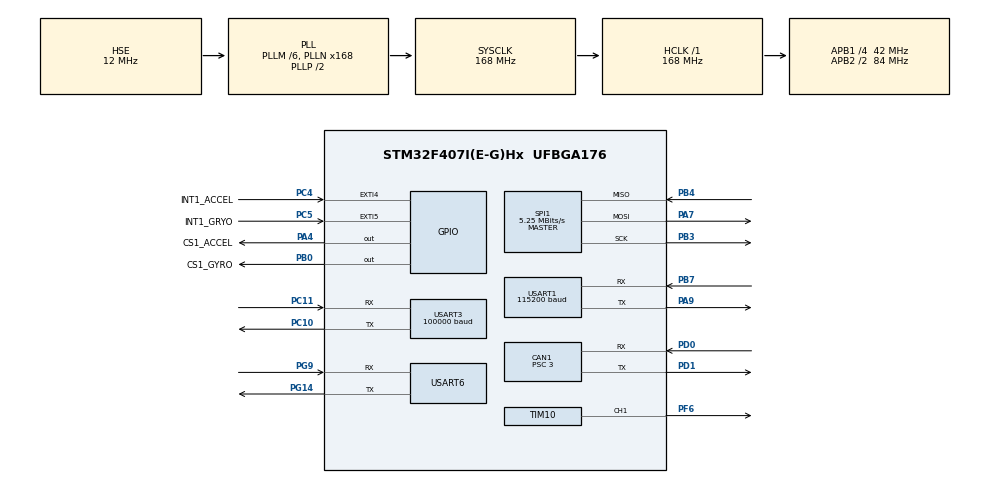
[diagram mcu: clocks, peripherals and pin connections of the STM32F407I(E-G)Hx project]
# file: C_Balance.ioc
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CAN1.ABOM=ENABLE
CAN1.AWUM=ENABLE
CAN1.BS1=CAN_BS1_9TQ
CAN1.BS2=CAN_BS2_4TQ
CAN1.CalculateBaudRate=1000000
CAN1.CalculateTimeBit=1000
CAN1.CalculateTimeQuantum=71.42857142857143
CAN1.Prescaler=3
CAN1.TXFP=ENABLE
Dma.Request0=SPI1_RX
Dma.Request1=SPI1_TX
Dma.Request2=USART3_RX
Dma.Request3=USART1_RX
Dma.Request4=USART1_TX
Dma.SPI1_RX.0.Direction=DMA_PERIPH_TO_MEMORY
Dma.SPI1_RX.0.FIFOMode=DMA_FIFOMODE_DISABLE
Dma.SPI1_RX.0.Instance=DMA2_Stream0
Dma.SPI1_RX.0.MemDataAlignment=DMA_MDATAALIGN_BYTE
Dma.SPI1_RX.0.MemInc=DMA_MINC_ENABLE
Dma.SPI1_RX.0.Mode=DMA_NORMAL
Dma.SPI1_RX.0.PeriphDataAlignment=DMA_PDATAALIGN_BYTE
Dma.SPI1_RX.0.PeriphInc=DMA_PINC_DISABLE
Dma.SPI1_RX.0.Priority=DMA_PRIORITY_VERY_HIGH
Dma.SPI1_TX.1.Direction=DMA_MEMORY_TO_PERIPH
Dma.SPI1_TX.1.FIFOMode=DMA_FIFOMODE_DISABLE
Dma.SPI1_TX.1.Instance=DMA2_Stream3
Dma.SPI1_TX.1.MemDataAlignment=DMA_MDATAALIGN_BYTE
Dma.SPI1_TX.1.MemInc=DMA_MINC_ENABLE
Dma.SPI1_TX.1.Mode=DMA_NORMAL
Dma.SPI1_TX.1.PeriphDataAlignment=DMA_PDATAALIGN_BYTE
Dma.SPI1_TX.1.PeriphInc=DMA_PINC_DISABLE
Dma.SPI1_TX.1.Priority=DMA_PRIORITY_HIGH
Dma.USART1_RX.3.Direction=DMA_PERIPH_TO_MEMORY
Dma.USART1_RX.3.FIFOMode=DMA_FIFOMODE_DISABLE
Dma.USART1_RX.3.Instance=DMA2_Stream2
Dma.USART1_RX.3.MemDataAlignment=DMA_MDATAALIGN_BYTE
Dma.USART1_RX.3.MemInc=DMA_MINC_ENABLE
Dma.USART1_RX.3.Mode=DMA_CIRCULAR
Dma.USART1_RX.3.PeriphDataAlignment=DMA_PDATAALIGN_BYTE
Dma.USART1_RX.3.PeriphInc=DMA_PINC_DISABLE
Dma.USART1_RX.3.Priority=DMA_PRIORITY_LOW
Dma.USART1_TX.4.Direction=DMA_MEMORY_TO_PERIPH
Dma.USART1_TX.4.FIFOMode=DMA_FIFOMODE_DISABLE
Dma.USART1_TX.4.Instance=DMA2_Stream7
Dma.USART1_TX.4.MemDataAlignment=DMA_MDATAALIGN_BYTE
Dma.USART1_TX.4.MemInc=DMA_MINC_ENABLE
Dma.USART1_TX.4.Mode=DMA_NORMAL
Dma.USART1_TX.4.PeriphDataAlignment=DMA_PDATAALIGN_BYTE
Dma.USART1_TX.4.PeriphInc=DMA_PINC_DISABLE
Dma.USART1_TX.4.Priority=DMA_PRIORITY_LOW
Dma.USART3_RX.2.Direction=DMA_PERIPH_TO_MEMORY
Dma.USART3_RX.2.FIFOMode=DMA_FIFOMODE_DISABLE
Dma.USART3_RX.2.Instance=DMA1_Stream1
Dma.USART3_RX.2.MemDataAlignment=DMA_MDATAALIGN_BYTE
Dma.USART3_RX.2.MemInc=DMA_MINC_ENABLE
Dma.USART3_RX.2.Mode=DMA_CIRCULAR
Dma.USART3_RX.2.PeriphDataAlignment=DMA_PDATAALIGN_BYTE
Dma.USART3_RX.2.PeriphInc=DMA_PINC_DISABLE
Dma.USART3_RX.2.Priority=DMA_PRIORITY_HIGH
FREERTOS.Tasks01=defaultTask,0,128,StartDefaultTask,Default,NULL,Dynamic,NULL,NULL;Priority_H1,2,1024,Task_H1,As weak,NULL,Dynamic,NULL,NULL;Priority_H2,2,1024,Task_H2,As weak,NULL,Dynamic,NULL,NULL;Priority_M,1,1024,Task_M,As weak,NULL,Dynamic,NULL,NULL
Mcu.Family=STM32F4
Mcu.Name=STM32F407I(E-G)Hx
Mcu.Package=UFBGA176
NVIC.CAN1_RX0_IRQn=true\:5\:0\:false\:false\:true\:true\:true\:true\:true
NVIC.DMA1_Stream1_IRQn=true\:5\:0\:false\:false\:true\:true\:false\:true\:true
NVIC.DMA2_Stream0_IRQn=true\:5\:0\:false\:false\:true\:true\:false\:true\:true
NVIC.DMA2_Stream2_IRQn=true\:5\:0\:false\:false\:true\:true\:false\:true\:true
NVIC.DMA2_Stream3_IRQn=true\:5\:0\:false\:false\:true\:true\:false\:true\:true
NVIC.DMA2_Stream7_IRQn=true\:5\:0\:false\:false\:true\:true\:false\:true\:true
NVIC.EXTI4_IRQn=true\:5\:0\:false\:false\:true\:true\:true\:true\:true
NVIC.EXTI9_5_IRQn=true\:5\:0\:false\:false\:true\:true\:true\:true\:true
NVIC.PriorityGroup=NVIC_PRIORITYGROUP_4
NVIC.TIM2_IRQn=true\:15\:0\:false\:false\:true\:false\:false\:true\:true
NVIC.TimeBase=TIM2_IRQn
NVIC.TimeBaseIP=TIM2
NVIC.USART1_IRQn=true\:5\:0\:false\:false\:true\:true\:true\:true\:true
NVIC.USART3_IRQn=true\:5\:0\:false\:false\:true\:true\:true\:true\:true
PA13.Mode=Serial_Wire
PA13.Signal=SYS_JTMS-SWDIO
PA14.Mode=Serial_Wire
PA14.Signal=SYS_JTCK-SWCLK
PA4.GPIO_Label=CS1_ACCEL
PA4.GPIO_PuPd=GPIO_PULLUP
PA4.GPIO_Speed=GPIO_SPEED_FREQ_HIGH
PA4.PinState=GPIO_PIN_SET
PA4.Signal=GPIO_Output
PA7.GPIO_PuPd=GPIO_PULLUP
PA7.Mode=Full_Duplex_Master
PA7.Signal=SPI1_MOSI
PA9.Mode=Asynchronous
PA9.Signal=USART1_TX
PB0.GPIO_Label=CS1_GYRO
PB0.GPIO_PuPd=GPIO_PULLUP
PB0.GPIO_Speed=GPIO_SPEED_FREQ_HIGH
PB0.PinState=GPIO_PIN_SET
PB0.Signal=GPIO_Output
PB3.GPIO_PuPd=GPIO_PULLUP
PB3.Mode=Full_Duplex_Master
PB3.Signal=SPI1_SCK
PB4.GPIO_PuPd=GPIO_PULLUP
PB4.Mode=Full_Duplex_Master
PB4.Signal=SPI1_MISO
PB7.Mode=Asynchronous
PB7.Signal=USART1_RX
PC10.Mode=Asynchronous
PC10.Signal=USART3_TX
PC11.Mode=Asynchronous
PC11.Signal=USART3_RX
PC4.GPIO_Label=INT1_ACCEL
PC4.GPIO_ModeDefaultEXTI=GPIO_MODE_IT_FALLING
PC4.GPIO_PuPd=GPIO_PULLUP
PC4.Signal=GPXTI4
PC5.GPIO_Label=INT1_GRYO
PC5.GPIO_ModeDefaultEXTI=GPIO_MODE_IT_FALLING
PC5.GPIO_PuPd=GPIO_PULLUP
PC5.Signal=GPXTI5
PD0.Mode=CAN_Activate
PD0.Signal=CAN1_RX
PD1.Mode=CAN_Activate
PD1.Signal=CAN1_TX
PF6.GPIO_PuPd=GPIO_PULLUP
PF6.GPIO_Speed=GPIO_SPEED_FREQ_HIGH
PF6.Signal=S_TIM10_CH1
PG14.Mode=Asynchronous
PG14.Signal=USART6_TX
PG9.Mode=Asynchronous
PG9.Signal=USART6_RX
PH0-OSC_IN.Mode=HSE-External-Oscillator
PH0-OSC_IN.Signal=RCC_OSC_IN
PH1-OSC_OUT.Mode=HSE-External-Oscillator
PH1-OSC_OUT.Signal=RCC_OSC_OUT
ProjectManager.HeapSize=0x200
ProjectManager.StackSize=0x400
ProjectManager.TargetToolchain=MDK-ARM V5.32
RCC.48MHZClocksFreq_Value=84000000
RCC.AHBFreq_Value=168000000
RCC.APB1CLKDivider=RCC_HCLK_DIV4
RCC.APB1Freq_Value=42000000
RCC.APB1TimFreq_Value=84000000
RCC.APB2CLKDivider=RCC_HCLK_DIV2
RCC.APB2Freq_Value=84000000
RCC.APB2TimFreq_Value=168000000
RCC.CortexFreq_Value=168000000
RCC.HCLKFreq_Value=168000000
RCC.HSE_VALUE=12000000
RCC.HSI_VALUE=16000000
RCC.LSE_VALUE=32768
RCC.PLLM=6
RCC.PLLN=168
RCC.PLLSourceVirtual=RCC_PLLSOURCE_HSE
RCC.SYSCLKFreq_VALUE=168000000
RCC.SYSCLKSource=RCC_SYSCLKSOURCE_PLLCLK
RCC.VCOOutputFreq_Value=336000000
SH.S_TIM10_CH1.0=TIM10_CH1,PWM Generation1 CH1
SPI1.BaudRatePrescaler=SPI_BAUDRATEPRESCALER_16
SPI1.CLKPhase=SPI_PHASE_2EDGE
SPI1.CLKPolarity=SPI_POLARITY_HIGH
SPI1.CalculateBaudRate=5.25 MBits/s
SPI1.Direction=SPI_DIRECTION_2LINES
SPI1.Mode=SPI_MODE_MASTER
SPI1.VirtualType=VM_MASTER
TIM10.Channel=TIM_CHANNEL_1
TIM10.Period=4999
USART1.BaudRate=115200
USART1.VirtualMode=VM_ASYNC
USART3.BaudRate=100000
USART3.Parity=PARITY_EVEN
USART3.StopBits=STOPBITS_2
USART3.VirtualMode=VM_ASYNC
USART3.WordLength=WORDLENGTH_9B
USART6.VirtualMode=VM_ASYNC
VP_FREERTOS_VS_CMSIS_V1.Mode=CMSIS_V1
VP_SYS_VS_tim2.Mode=TIM2
VP_TIM10_VS_ClockSourceINT.Mode=Enable_Timer
board=custom

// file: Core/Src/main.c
/* USER CODE BEGIN Header */
/**
  ******************************************************************************
  * @file           : main.c
  * @brief          : Main program body
  ******************************************************************************
  * @attention
  *
  * Copyright (c) 2023 STMicroelectronics.
  * All rights reserved.
  *
  * This software is licensed under terms that can be found in the LICENSE file
  * in the root directory of this software component.
  * If no LICENSE file comes with this software, it is provided AS-IS.
  *
  ******************************************************************************
  */
/* USER CODE END Header */
#include "main.h"
#include "cmsis_os.h"
#include "can.h"
#include "dma.h"
#include "spi.h"
#include "tim.h"
#include "usart.h"
#include "gpio.h"

/* USER CODE BEGIN Includes */
#include "BMI088driver.h"
#include "drv_can.h"
#include "dev_all.h"
#include "drv_uart.h"
/* USER CODE END Includes */

void SystemClock_Config(void);
void MX_FREERTOS_Init(void);

int main(void)
{

  /* MCU Configuration--------------------------------------------------------*/

  /* Reset of all peripherals, Initializes the Flash interface and the Systick. */
  HAL_Init();

  /* Configure the system clock */
  SystemClock_Config();

  /* Initialize all configured peripherals */
  MX_GPIO_Init();
  MX_DMA_Init();
  MX_SPI1_Init();
  MX_TIM10_Init();
  MX_CAN1_Init();
  MX_USART3_UART_Init();
  MX_USART1_UART_Init();
  MX_USART6_UART_Init();
  /* USER CODE BEGIN 2 */

  while(BMI088_init())
  {
      ;
  }

	CAN1_Init();
	USART1_Init();
	USART3_Init();
	My_Device_Init();
  /* USER CODE END 2 */

  /* Call init function for freertos objects (in freertos.c) */
  MX_FREERTOS_Init();

  /* Start scheduler */
  osKernelStart();

  /* We should never get here as control is now taken by the scheduler */
  /* Infinite loop */
  while (1)
  {

  }
}

void SystemClock_Config(void)
{
  RCC_OscInitTypeDef RCC_OscInitStruct = {0};
  RCC_ClkInitTypeDef RCC_ClkInitStruct = {0};

  /** Configure the main internal regulator output voltage
  */
  __HAL_RCC_PWR_CLK_ENABLE();
  __HAL_PWR_VOLTAGESCALING_CONFIG(PWR_REGULATOR_VOLTAGE_SCALE1);

  /** Initializes the RCC Oscillators according to the specified parameters
  * in the RCC_OscInitTypeDef structure.
  */
  RCC_OscInitStruct.OscillatorType = RCC_OSCILLATORTYPE_HSE;
  RCC_OscInitStruct.HSEState = RCC_HSE_ON;
  RCC_OscInitStruct.PLL.PLLState = RCC_PLL_ON;
  RCC_OscInitStruct.PLL.PLLSource = RCC_PLLSOURCE_HSE;
  RCC_OscInitStruct.PLL.PLLM = 6;
  RCC_OscInitStruct.PLL.PLLN = 168;
  RCC_OscInitStruct.PLL.PLLP = RCC_PLLP_DIV2;
  RCC_OscInitStruct.PLL.PLLQ = 4;
  if (HAL_RCC_OscConfig(&RCC_OscInitStruct) != HAL_OK)
  {
    Error_Handler();
  }

  /** Initializes the CPU, AHB and APB buses clocks
  */
  RCC_ClkInitStruct.ClockType = RCC_CLOCKTYPE_HCLK|RCC_CLOCKTYPE_SYSCLK
                              |RCC_CLOCKTYPE_PCLK1|RCC_CLOCKTYPE_PCLK2;
  RCC_ClkInitStruct.SYSCLKSource = RCC_SYSCLKSOURCE_PLLCLK;
  RCC_ClkInitStruct.AHBCLKDivider = RCC_SYSCLK_DIV1;
  RCC_ClkInitStruct.APB1CLKDivider = RCC_HCLK_DIV4;
  RCC_ClkInitStruct.APB2CLKDivider = RCC_HCLK_DIV2;

  if (HAL_RCC_ClockConfig(&RCC_ClkInitStruct, FLASH_LATENCY_5) != HAL_OK)
  {
    Error_Handler();
  }
}

void HAL_TIM_PeriodElapsedCallback(TIM_HandleTypeDef *htim)
{
  if (htim->Instance == TIM2) {
    HAL_IncTick();
  }
}

void Error_Handler(void)
{
  __disable_irq();
  while (1)
  {
  }
}
